VERSION ""

NS_ :

BS_:

BU_:
VAL_TABLE_ VCU_STATES 6 "VCU_DRIVE" 5 "VCU_BUZZER" 4 "VCU_START_INVERTER" 3 "VCU_WAIT_R2D" 2 "VCU_CLOSE_CONTACTORS" 1 "VCU_IDLE" 0 "VCU_ERROR" ;

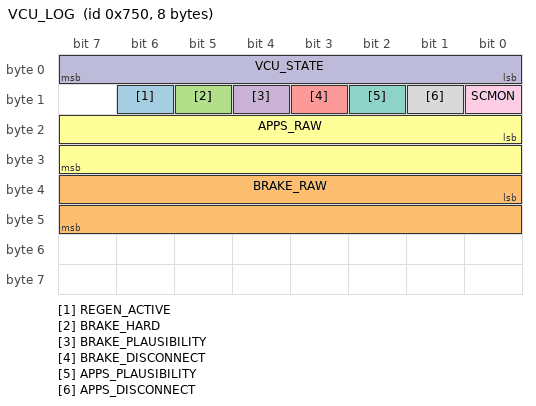
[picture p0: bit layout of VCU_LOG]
BO_ 1872 VCU_LOG: 8 Vector__XXX
 SG_ REGEN_ACTIVE : 14|1@1+ (1,0) [0|1] "" Vector__XXX
 SG_ BRAKE_RAW : 32|16@1+ (1,0) [0|65535] "" Vector__XXX
 SG_ BRAKE_HARD : 13|1@1+ (1,0) [0|1] "" Vector__XXX
 SG_ BRAKE_PLAUSIBILITY : 12|1@1+ (1,0) [0|1] "" Vector__XXX
 SG_ BRAKE_DISCONNECT : 11|1@1+ (1,0) [0|1] "" Vector__XXX
 SG_ APPS_RAW : 16|16@1+ (1,0) [0|65535] "" Vector__XXX
 SG_ APPS_PLAUSIBILITY : 10|1@1+ (1,0) [0|1] "" Vector__XXX
 SG_ APPS_DISCONNECT : 9|1@1+ (1,0) [0|1] "" Vector__XXX
 SG_ SCMON : 8|1@1+ (1,0) [0|1] "" Vector__XXX
 SG_ VCU_STATE : 0|8@1+ (1,0) [0|255] "" Vector__XXX

VAL_ 1872 VCU_STATE 6 "VCU_DRIVE" 5 "VCU_BUZZER" 4 "VCU_START_INVERTER" 3 "VCU_WAIT_R2D" 2 "VCU_CLOSE_CONTACTORS" 1 "VCU_IDLE" 0 "VCU_ERROR" ;
